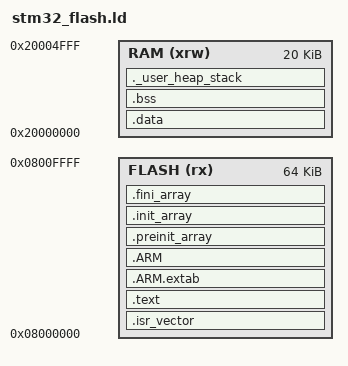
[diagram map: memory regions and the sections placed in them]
/*
*****************************************************************************
**
**  File        : stm32_flash.ld
**
**  Abstract    : Linker script for STM32F407VG Device with
**                1024KByte FLASH, 192KByte RAM
**
**                Set heap size, stack size and stack location according
**                to application requirements.
**
**                Set memory bank area and size if external memory is used.
**
**  Target      : STMicroelectronics STM32
**
**  Environment : Atollic TrueSTUDIO(R)
**
**  Distribution: The file is distributed �as is,� without any warranty
**                of any kind.
**
**  (c)Copyright Atollic AB.
**  You may use this file as-is or modify it according to the needs of your
**  project. Distribution of this file (unmodified or modified) is not
**  permitted. Atollic AB permit registered Atollic TrueSTUDIO(R) users the
**  rights to distribute the assembled, compiled & linked contents of this
**  file as part of an application binary file, provided that it is built
**  using the Atollic TrueSTUDIO(R) toolchain.
**
*****************************************************************************
*/

/* Entry Point */
/*ENTRY(Reset_Handler)*/
/* Linker script for STM32F4xx ARM(R) Cortex(TM)-M4 MCU */

INPUT(libc.a libm.a libgcc.a)

OUTPUT_FORMAT("elf32-littlearm", "elf32-littlearm", "elf32-littlearm")
OUTPUT_ARCH(arm)

/* The beginning and end of the program ROM area */
/* Set up a ROM area with a size of 32K - 4 */
_rom_begin = 0x08000000;
_rom_end   = 0x800FA00;

/* The beginning and end (i.e., the top) of the stack */
/* Set up a stack with a size of 4K */
_stack_begin = 0x20003C00;
_stack_end   = 0x20004000;

__initial_stack_pointer = 0x20002000;

/* Generate a link error if heap and stack don't fit into RAM */
_Min_Heap_Size = 0x200 ; /* required amount of heap */
_Min_Stack_Size = 0x400 ; /* required amount of stack */


/* Specify the memory areas */
MEMORY
{
  RAM    (xrw)    : ORIGIN = 0x20000000,   LENGTH = 20K
  FLASH    (rx)    : ORIGIN = 0x8000000,   LENGTH = 64K
 /* MEMORY_B1 (rx)  : ORIGIN = 0x60000000, LENGTH = 0K*/
}

/* Define output sections */
SECTIONS
{
  /* The startup code goes first into FLASH */
  . = 0x08000000;
  . = ALIGN(4);

  /* ISR vectors */
  .isr_vector :
  {
    *(.isr_vector)
    . = ALIGN(0x10);
    KEEP(*(.isr_vector))
  } > FLASH = 0xAAAA


  /* The program code and other data goes into FLASH */
  .text :
  {
    _ctors_begin = .;
    *(.init_array)
    . = ALIGN(4);
    KEEP (*(SORT(.init_array)))
    _ctors_end = .;
    *(.text)           /* .text sections (code) */
    *(.text*)          /* .text* sections (code) */
    *(.rodata)         /* .rodata sections (constants, strings, etc.) */
    *(.rodata*)        /* .rodata* sections (constants, strings, etc.) */
    *(.glue_7)         /* glue arm to thumb code */
    *(.glue_7t)        /* glue thumb to arm code */
	*(.eh_frame)

  } >FLASH

 .ARM.extab   : { *(.ARM.extab* .gnu.linkonce.armextab.*) } >FLASH
    .ARM : {
    __exidx_start = .;
      *(.ARM.exidx*)
      __exidx_end = .;
    } >FLASH

  .preinit_array     :
  {
    PROVIDE_HIDDEN (__preinit_array_start = .);
    KEEP (*(.preinit_array*))
    PROVIDE_HIDDEN (__preinit_array_end = .);
  } >FLASH
  .init_array :
  {
    PROVIDE_HIDDEN (__init_array_start = .);
    KEEP (*(SORT(.init_array.*)))
    KEEP (*(.init_array*))
    PROVIDE_HIDDEN (__init_array_end = .);
  } >FLASH
  .fini_array :
  {
    PROVIDE_HIDDEN (__fini_array_start = .);
    KEEP (*(.fini_array*))
    KEEP (*(SORT(.fini_array.*)))
    PROVIDE_HIDDEN (__fini_array_end = .);
  } >FLASH

  
  /* used by the startup to initialize data */
  _sidata = .;

  /* Initialized data sections goes into RAM, load LMA copy after code */
  .data : AT ( _sidata )
  {
    _data_begin = .;
    *(.data)
    . = ALIGN(4);
    KEEP (*(.data))
    *(.data*)
    . = ALIGN(4);
    KEEP (*(.data*))
    _data_end = .;
  } >RAM

  /* Uninitialized data section */
  . = ALIGN(4);
  .bss :
  {
  /* This is used by the startup in order to initialize the .bss secion */
     _bss_begin = .;  /* define a global symbol at bss start */
     __bss_start__ = .;
    *(.bss)
    *(.bss)
    *(.bss*)
    *(COMMON)
    . = ALIGN(4);
    KEEP (*(.bss))
    *(.bss*)
    . = ALIGN(4);
    KEEP (*(.bss*))
    _bss_end = .; /* define a global symbol at bss end */
    __bss_end__ = _bss_end;
   } >RAM

  /* User_heap_stack section, used to check that there is enough RAM left */
  ._user_heap_stack :
  {
    . = ALIGN(4);
    PROVIDE ( end = . );
    PROVIDE ( _end = . );
    . = . + _Min_Heap_Size;
    . = . + _Min_Stack_Size;
    . = ALIGN(4);
  } >RAM

  /* MEMORY_bank1 section, code must be located here explicitly            */
  /* Example: extern int foo(void) __attribute__ ((section (".mb1text"))); */
  /*
  .memory_b1_text :
  {
    *(.mb1text)       
    *(.mb1text*)      
    *(.mb1rodata)       
    *(.mb1rodata*)
  } >MEMORY_B1
*/
  /* Remove information from the standard libraries */
  /DISCARD/ :
  {
    libc.a ( * )
    libm.a ( * )
    libgcc.a ( * )
  }
  _rom_data_begin = LOADADDR(.data);

  .ARM.attributes 0 : { *(.ARM.attributes) }
}
 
